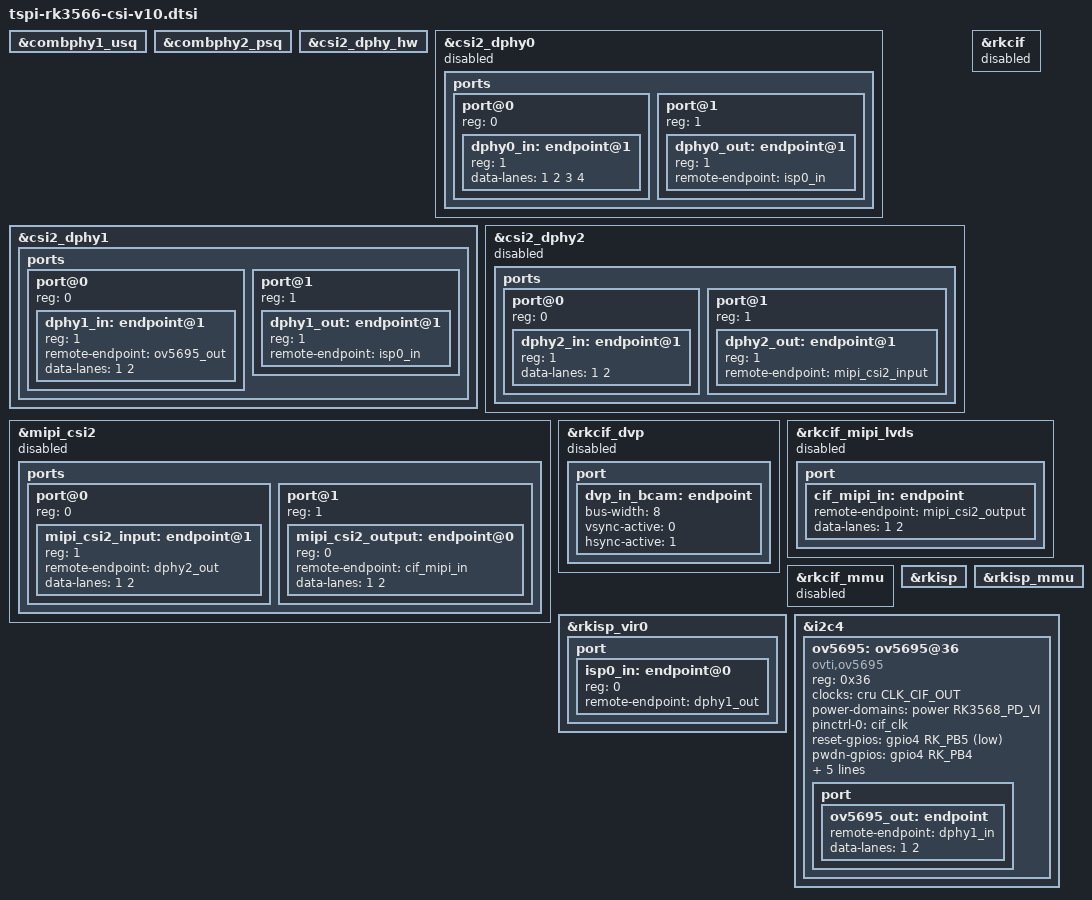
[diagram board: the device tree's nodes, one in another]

/*********************************************************************
 *           立创开发板不靠卖板赚钱，以培养中国工程师为己任  
 *         泰山派软硬件资料与相关扩展板软硬件资料官网全部开源
 *                      开发板官网：www.lckfb.com            
 *                     立创论坛：oshwhub.com/forum           
 *            关注B站：【立创开发板】，掌握我们的最新动态！  
 *********************************************************************
 * 文件名：tspi-rk3566-csi-v10
 * 描述：mipi 摄像头
 * 更新:
 * 时间          作者           联系           说明
 * 2023-09-13   吴才成    1378913492@qq.com   v1.0.0
 *********************************************************************/

//phy u序列
&combphy1_usq {
	status = "okay";
};

//phy P序列
&combphy2_psq {
	status = "okay";
};

//dphy硬件
&csi2_dphy_hw {
	status = "okay";
};
//摄像头D-PHY接口
&csi2_dphy0 {
	status = "disabled";
	/*
	 * dphy0 only used for full mode,
	 * full mode and split mode are mutually exclusive
	 */
	ports {
		#address-cells = <1>;
		#size-cells = <0>;

		port@0 {
			reg = <0>;
			#address-cells = <1>;
			#size-cells = <0>;

			dphy0_in: endpoint@1 {
				reg = <1>;
				// remote-endpoint = <&gc8034_out>;
				data-lanes = <1 2 3 4>;
			};
		};

		port@1 {
			reg = <1>;
			#address-cells = <1>;
			#size-cells = <0>;

			dphy0_out: endpoint@1 {
				reg = <1>;
				remote-endpoint = <&isp0_in>;
			};
		};
	};
};

//摄像头D-PHY接口
&csi2_dphy1 {
	status = "okay";

	/*
	 * dphy1 only used for split mode,
	 * can be used  concurrently  with dphy2
	 * full mode and split mode are mutually exclusive
	 */
	ports {
		#address-cells = <1>;
		#size-cells = <0>;

		port@0 {
			reg = <0>;
			#address-cells = <1>;
			#size-cells = <0>;

			dphy1_in: endpoint@1 {
				reg = <1>;
				remote-endpoint = <&ov5695_out>;
				data-lanes = <1 2>;
			};
		};

		port@1 {
			reg = <1>;
			#address-cells = <1>;
			#size-cells = <0>;

			dphy1_out: endpoint@1 {
				reg = <1>;
				remote-endpoint = <&isp0_in>;
			};
		};
	};
};
//摄像头D-PHY接口
&csi2_dphy2 {
	status = "disabled";

	/*
	 * dphy2 only used for split mode,
	 * can be used  concurrently  with dphy1
	 * full mode and split mode are mutually exclusive
	 */
	ports {
		#address-cells = <1>;
		#size-cells = <0>;

		port@0 {
			reg = <0>;
			#address-cells = <1>;
			#size-cells = <0>;

			dphy2_in: endpoint@1 {
				reg = <1>;
				//remote-endpoint = <&gc5025_out>;
				data-lanes = <1 2>;
			};
		};

		port@1 {
			reg = <1>;
			#address-cells = <1>;
			#size-cells = <0>;

			dphy2_out: endpoint@1 {
				reg = <1>;
				remote-endpoint = <&mipi_csi2_input>;
			};
		};
	};
};



&mipi_csi2 {
	status = "disabled";

	ports {
		#address-cells = <1>;
		#size-cells = <0>;

		port@0 {
			reg = <0>;
			#address-cells = <1>;
			#size-cells = <0>;

			mipi_csi2_input: endpoint@1 {
				reg = <1>;
				remote-endpoint = <&dphy2_out>;
				data-lanes = <1 2>;
			};
		};

		port@1 {
			reg = <1>;
			#address-cells = <1>;
			#size-cells = <0>;

			mipi_csi2_output: endpoint@0 {
				reg = <0>;
				remote-endpoint = <&cif_mipi_in>;
				data-lanes = <1 2>;
			};
		};
	};
};

//Rockchip Camera Interface
&rkcif {
	status = "disabled";
};

//dvp接口摄像头
&rkcif_dvp {
	status = "disabled";

	port {
		/* Parallel bus endpoint */
		dvp_in_bcam: endpoint {
			// remote-endpoint = <&gc2145_out>;
			bus-width = <8>;
			vsync-active = <0>;
			hsync-active = <1>;
		};
	};
};

//LVDS接口摄像头
&rkcif_mipi_lvds {
	status = "disabled";

	port {
		cif_mipi_in: endpoint {
			remote-endpoint = <&mipi_csi2_output>;
			data-lanes = <1 2>;
		};
	};
};

//摄像头内存管理
&rkcif_mmu {
	status = "disabled";
};

//硬件图像处理器模块
&rkisp {
	status = "okay";
};

//硬件图像处理器模块内存管理器
&rkisp_mmu {
	status = "okay";
};

//图像处理接口
&rkisp_vir0 {
	status = "okay";

	port {
		#address-cells = <1>;
		#size-cells = <0>;

		isp0_in: endpoint@0 {
			reg = <0>;
			remote-endpoint = <&dphy1_out>;
		};
	};
};

&i2c4 {
	/* i2c4 sda conflict with camera pwdn */
	status = "okay";
	ov5695: ov5695@36 {
		status = "okay";
		compatible = "ovti,ov5695";
		reg = <0x36>;
		clocks = <&cru CLK_CIF_OUT>;
		clock-names = "xvclk";
		power-domains = <&power RK3568_PD_VI>;
		pinctrl-names = "default";
		pinctrl-0 = <&cif_clk>;
        reset-gpios = <&gpio4 RK_PB5 GPIO_ACTIVE_LOW>;
		pwdn-gpios = <&gpio4 RK_PB4 GPIO_ACTIVE_HIGH>;
		power-gpios = <&gpio0 RK_PB0 GPIO_ACTIVE_HIGH>;
		rockchip,camera-module-index = <0>;
		rockchip,camera-module-facing = "back";
        rockchip,camera-module-name = "TongJu";
		rockchip,camera-module-lens-name = "CHT842-MD";
		port {
			ov5695_out: endpoint {
				remote-endpoint = <&dphy1_in>;
				data-lanes = <1 2>;
			};
		};
	};
};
